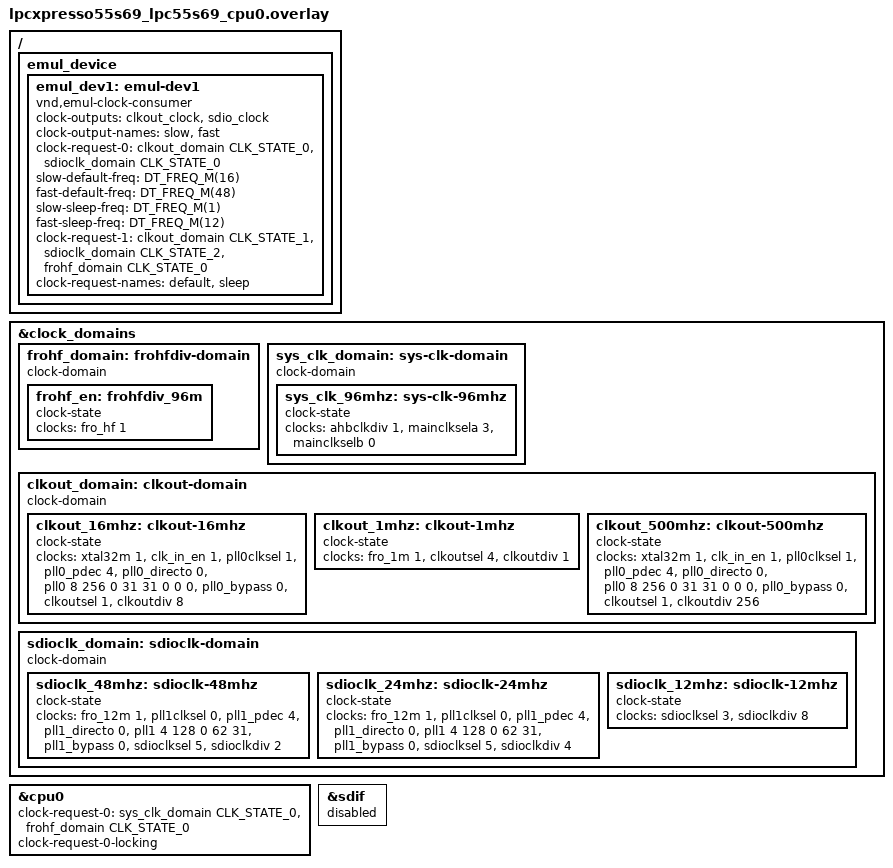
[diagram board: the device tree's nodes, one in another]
/*
 * Copyright (c) 2024 Tenstorrent AI ULC
 * Copyright (c) 2026 Analog Devices, Inc
 *
 * SPDX-License-Identifier: Apache-2.0
 */

#include <freq.h>
#include <zephyr/dt-bindings/clock-management/clock-management.h>

&clock_domains {
	frohf_domain: frohfdiv-domain {
		compatible = "clock-domain";
		#clock-state-cells = <1>;
		/* FROHF clock domain */
		frohf_en: frohfdiv_96m {
			compatible = "clock-state";
			clocks = <&fro_hf 1>;
		};
	};

	sys_clk_domain: sys-clk-domain {
		/delete-node/ sys_clk_144mhz;
		compatible = "clock-domain";
		/* Clock CPU from FROHF, since we will use the PLLs within our testcases */
		sys_clk_96mhz: sys-clk-96mhz {
			compatible = "clock-state";
			clocks = <&ahbclkdiv 1 &mainclksela 3 &mainclkselb 0>;
		};
	};

	/* Define clock states for clockout clock */
	clkout_domain: clkout-domain {
		compatible = "clock-domain";
		#clock-state-cells = <1>;
		clkout_16mhz: clkout-16mhz {
			compatible = "clock-state";
			/* Expect a clock frequency of 16 MHz */
			clocks = <&xtal32m 1 &clk_in_en 1 &pll0clksel 1
				  &pll0_pdec 4 &pll0_directo 0
				  &pll0 8 256 0 31 31 0 0 0
				  &pll0_bypass 0 &clkoutsel 1
				  &clkoutdiv 8>;
		};

		clkout_1mhz: clkout-1mhz {
			compatible = "clock-state";
			/* Expect a clock frequency of 1MHz */
			clocks = <&fro_1m 1 &clkoutsel 4 &clkoutdiv 1>;
		};

		clkout_500mhz: clkout-500mhz {
			compatible = "clock-state";
			/* Expect a clock frequency of 500 KHz */
			clocks = <&xtal32m 1 &clk_in_en 1 &pll0clksel 1
				  &pll0_pdec 4 &pll0_directo 0
				  &pll0 8 256 0 31 31 0 0 0
				  &pll0_bypass 0 &clkoutsel 1
				  &clkoutdiv 256>;
		};
	};

	/* Define clock states for SDIO clock */
	sdioclk_domain: sdioclk-domain {
		compatible = "clock-domain";
		#clock-state-cells = <1>;
		sdioclk_48mhz: sdioclk-48mhz {
			compatible = "clock-state";
			/* Expect a clock frequency of 48 MHz */
			clocks = <&fro_12m 1 &pll1clksel 0
				  &pll1_pdec 4 &pll1_directo 0
				  &pll1 4 128 0 62 31
				  &pll1_bypass 0 &sdioclksel 5
				  &sdioclkdiv 2>;
		};

		sdioclk_24mhz: sdioclk-24mhz {
			compatible = "clock-state";
			/* Expect a clock frequency of 24 MHz */
			clocks = <&fro_12m 1 &pll1clksel 0
				  &pll1_pdec 4 &pll1_directo 0
				  &pll1 4 128 0 62 31
				  &pll1_bypass 0 &sdioclksel 5
				  &sdioclkdiv 4>;
		};

		sdioclk_12mhz: sdioclk-12mhz {
			compatible = "clock-state";
			/* Expect a clock frequency of 12 MHz */
			clocks = <&sdioclksel 3
				  &sdioclkdiv 8>;
		};
	};
};

&cpu0 {
	clock-request-0 = <&sys_clk_domain CLK_STATE_0 &frohf_domain CLK_STATE_0>;
	clock-request-0-locking;
};

/* Disable the SD controller- we are using its clock for this test */
&sdif {
	status = "disabled";
};

/ {
	/* Emulated device clock consumer */
	emul_device {
		emul_dev1: emul-dev1 {
			compatible = "vnd,emul-clock-consumer";
			clock-outputs = <&clkout_clock &sdio_clock>;
			clock-output-names = "slow", "fast";
			clock-request-0 = <&clkout_domain CLK_STATE_0 &sdioclk_domain CLK_STATE_0>;
			slow-default-freq = <DT_FREQ_M(16)>;
			fast-default-freq = <DT_FREQ_M(48)>;
			slow-sleep-freq = <DT_FREQ_M(1)>;
			fast-sleep-freq = <DT_FREQ_M(12)>;
			clock-request-1 = <&clkout_domain CLK_STATE_1 &sdioclk_domain CLK_STATE_2
					   &frohf_domain CLK_STATE_0>;
			clock-request-names = "default", "sleep";
		};
	};
};
